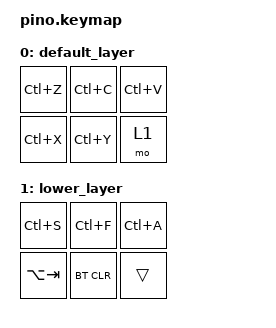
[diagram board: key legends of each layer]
#include <behaviors.dtsi>
#include <dt-bindings/zmk/keys.h>
#include <dt-bindings/zmk/bt.h>
#include <dt-bindings/zmk/outputs.h>

/ {
    keymap {
        compatible = "zmk,keymap";

        default_layer {
            bindings = 
                &kp LC(Z)      &kp LC(C)   &kp LC(V)
                &kp LC(X)      &kp LC(Y)   &mo 1
            >;
        };

        lower_layer {
            bindings = 
                &kp LC(S)      &kp LC(F)   &kp LC(A)
                &kp LA(TAB)    &bt BT_CLR  &trans
            >;
        };
    };
};
